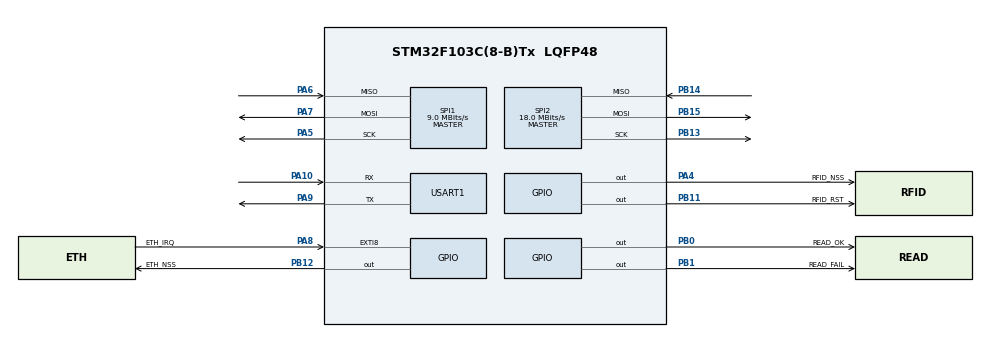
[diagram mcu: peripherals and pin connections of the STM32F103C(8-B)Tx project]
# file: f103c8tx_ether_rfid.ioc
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Mcu.Family=STM32F1
Mcu.Name=STM32F103C(8-B)Tx
Mcu.Package=LQFP48
NVIC.PriorityGroup=NVIC_PRIORITYGROUP_4
PA10.Mode=Asynchronous
PA10.Signal=USART1_RX
PA13.Mode=Trace_Asynchronous_SW
PA13.Signal=SYS_JTMS-SWDIO
PA14.Mode=Trace_Asynchronous_SW
PA14.Signal=SYS_JTCK-SWCLK
PA4.GPIO_Label=RFID_NSS
PA4.GPIO_Speed=GPIO_SPEED_FREQ_HIGH
PA4.PinState=GPIO_PIN_SET
PA4.Signal=GPIO_Output
PA5.Mode=Full_Duplex_Master
PA5.Signal=SPI1_SCK
PA6.Mode=Full_Duplex_Master
PA6.Signal=SPI1_MISO
PA7.Mode=Full_Duplex_Master
PA7.Signal=SPI1_MOSI
PA8.GPIO_Label=ETH_IRQ
PA8.GPIO_ModeDefaultEXTI=GPIO_MODE_IT_FALLING
PA8.GPIO_PuPd=GPIO_PULLUP
PA8.Signal=GPXTI8
PA9.Mode=Asynchronous
PA9.Signal=USART1_TX
PB0.GPIO_Label=READ_OK
PB0.GPIO_Speed=GPIO_SPEED_FREQ_HIGH
PB0.Signal=GPIO_Output
PB1.GPIO_Label=READ_FAIL
PB1.GPIO_Speed=GPIO_SPEED_FREQ_HIGH
PB1.Signal=GPIO_Output
PB11.GPIO_Label=RFID_RST
PB11.GPIO_Speed=GPIO_SPEED_FREQ_HIGH
PB11.Signal=GPIO_Output
PB12.GPIO_Label=ETH_NSS
PB12.GPIO_Speed=GPIO_SPEED_FREQ_HIGH
PB12.PinState=GPIO_PIN_SET
PB12.Signal=GPIO_Output
PB13.Mode=Full_Duplex_Master
PB13.Signal=SPI2_SCK
PB14.Mode=Full_Duplex_Master
PB14.Signal=SPI2_MISO
PB15.Mode=Full_Duplex_Master
PB15.Signal=SPI2_MOSI
PB3.Mode=Trace_Asynchronous_SW
PB3.Signal=SYS_JTDO-TRACESWO
PD0-OSC_IN.Mode=HSE-External-Oscillator
PD0-OSC_IN.Signal=RCC_OSC_IN
PD1-OSC_OUT.Mode=HSE-External-Oscillator
PD1-OSC_OUT.Signal=RCC_OSC_OUT
ProjectManager.HeapSize=0x200
ProjectManager.StackSize=0x400
ProjectManager.TargetToolchain=CMake
RCC.AHBFreq_Value=72000000
RCC.APB1CLKDivider=RCC_HCLK_DIV2
RCC.APB1Freq_Value=36000000
RCC.APB1TimFreq_Value=72000000
RCC.APB2Freq_Value=72000000
RCC.APB2TimFreq_Value=72000000
RCC.HCLKFreq_Value=72000000
RCC.PLLMUL=RCC_PLL_MUL9
RCC.PLLSourceVirtual=RCC_PLLSOURCE_HSE
RCC.SYSCLKFreq_VALUE=72000000
RCC.SYSCLKSource=RCC_SYSCLKSOURCE_PLLCLK
RCC.USBFreq_Value=72000000
SPI1.BaudRatePrescaler=SPI_BAUDRATEPRESCALER_8
SPI1.CalculateBaudRate=9.0 MBits/s
SPI1.Direction=SPI_DIRECTION_2LINES
SPI1.Mode=SPI_MODE_MASTER
SPI1.VirtualType=VM_MASTER
SPI2.CalculateBaudRate=18.0 MBits/s
SPI2.Direction=SPI_DIRECTION_2LINES
SPI2.Mode=SPI_MODE_MASTER
SPI2.VirtualType=VM_MASTER
USART1.VirtualMode=VM_ASYNC
board=custom

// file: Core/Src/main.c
/* USER CODE BEGIN Header */
/**
  ******************************************************************************
  * @file           : main.c
  * @brief          : Main program body
  ******************************************************************************
  * @attention
  *
  * Copyright (c) 2024 STMicroelectronics.
  * All rights reserved.
  *
  * This software is licensed under terms that can be found in the LICENSE file
  * in the root directory of this software component.
  * If no LICENSE file comes with this software, it is provided AS-IS.
  *
  ******************************************************************************
  */
/* USER CODE END Header */
#include "main.h"

/* USER CODE BEGIN Includes */
#include "app.h"
/* USER CODE END Includes */

void SystemClock_Config(void);
static void MX_GPIO_Init(void);
static void MX_SPI1_Init(void);
static void MX_SPI2_Init(void);
static void MX_USART1_UART_Init(void);

/* USER CODE BEGIN 0 */
int _write(int file, char *ptr, int len)
{
  for(int i = 0; i < len; i++)
  {
    while (!(LL_USART_IsActiveFlag_TXE(USART1)))
      ;
    LL_USART_TransmitData8(USART1, *ptr++);
  }
  return len;
}
/* USER CODE END 0 */

int main(void)
{

  /* MCU Configuration--------------------------------------------------------*/

  /* Reset of all peripherals, Initializes the Flash interface and the Systick. */
  LL_APB2_GRP1_EnableClock(LL_APB2_GRP1_PERIPH_AFIO);
  LL_APB1_GRP1_EnableClock(LL_APB1_GRP1_PERIPH_PWR);

  /* System interrupt init*/
  NVIC_SetPriorityGrouping(NVIC_PRIORITYGROUP_4);

  /* SysTick_IRQn interrupt configuration */
  NVIC_SetPriority(SysTick_IRQn, NVIC_EncodePriority(NVIC_GetPriorityGrouping(),15, 0));

  /** NOJTAG: JTAG-DP Disabled and SW-DP Enabled
  */
  LL_GPIO_AF_Remap_SWJ_NOJTAG();

  /* Configure the system clock */
  SystemClock_Config();

  /* Initialize all configured peripherals */
  MX_GPIO_Init();
  MX_SPI1_Init();
  MX_SPI2_Init();
  MX_USART1_UART_Init();
  /* USER CODE BEGIN 2 */
  app_main();
  /* USER CODE END 2 */

  /* Infinite loop */
  while (1)
  {

  }
}

void SystemClock_Config(void)
{
  LL_FLASH_SetLatency(LL_FLASH_LATENCY_2);
  while(LL_FLASH_GetLatency()!= LL_FLASH_LATENCY_2)
  {
  }
  LL_RCC_HSE_Enable();

   /* Wait till HSE is ready */
  while(LL_RCC_HSE_IsReady() != 1)
  {

  }
  LL_RCC_PLL_ConfigDomain_SYS(LL_RCC_PLLSOURCE_HSE_DIV_1, LL_RCC_PLL_MUL_9);
  LL_RCC_PLL_Enable();

   /* Wait till PLL is ready */
  while(LL_RCC_PLL_IsReady() != 1)
  {

  }
  LL_RCC_SetAHBPrescaler(LL_RCC_SYSCLK_DIV_1);
  LL_RCC_SetAPB1Prescaler(LL_RCC_APB1_DIV_2);
  LL_RCC_SetAPB2Prescaler(LL_RCC_APB2_DIV_1);
  LL_RCC_SetSysClkSource(LL_RCC_SYS_CLKSOURCE_PLL);

   /* Wait till System clock is ready */
  while(LL_RCC_GetSysClkSource() != LL_RCC_SYS_CLKSOURCE_STATUS_PLL)
  {

  }
  LL_Init1msTick(72000000);
  LL_SetSystemCoreClock(72000000);
}

static void MX_SPI1_Init(void)
{

  LL_SPI_InitTypeDef SPI_InitStruct = {0};

  LL_GPIO_InitTypeDef GPIO_InitStruct = {0};

  /* Peripheral clock enable */
  LL_APB2_GRP1_EnableClock(LL_APB2_GRP1_PERIPH_SPI1);

  LL_APB2_GRP1_EnableClock(LL_APB2_GRP1_PERIPH_GPIOA);
  /**SPI1 GPIO Configuration
  PA5   ------> SPI1_SCK
  PA6   ------> SPI1_MISO
  PA7   ------> SPI1_MOSI
  */
  GPIO_InitStruct.Pin = LL_GPIO_PIN_5|LL_GPIO_PIN_7;
  GPIO_InitStruct.Mode = LL_GPIO_MODE_ALTERNATE;
  GPIO_InitStruct.Speed = LL_GPIO_SPEED_FREQ_HIGH;
  GPIO_InitStruct.OutputType = LL_GPIO_OUTPUT_PUSHPULL;
  LL_GPIO_Init(GPIOA, &GPIO_InitStruct);

  GPIO_InitStruct.Pin = LL_GPIO_PIN_6;
  GPIO_InitStruct.Mode = LL_GPIO_MODE_FLOATING;
  LL_GPIO_Init(GPIOA, &GPIO_InitStruct);

  /* SPI1 parameter configuration*/
  SPI_InitStruct.TransferDirection = LL_SPI_FULL_DUPLEX;
  SPI_InitStruct.Mode = LL_SPI_MODE_MASTER;
  SPI_InitStruct.DataWidth = LL_SPI_DATAWIDTH_8BIT;
  SPI_InitStruct.ClockPolarity = LL_SPI_POLARITY_LOW;
  SPI_InitStruct.ClockPhase = LL_SPI_PHASE_1EDGE;
  SPI_InitStruct.NSS = LL_SPI_NSS_SOFT;
  SPI_InitStruct.BaudRate = LL_SPI_BAUDRATEPRESCALER_DIV8;
  SPI_InitStruct.BitOrder = LL_SPI_MSB_FIRST;
  SPI_InitStruct.CRCCalculation = LL_SPI_CRCCALCULATION_DISABLE;
  SPI_InitStruct.CRCPoly = 10;
  LL_SPI_Init(SPI1, &SPI_InitStruct);

}

static void MX_SPI2_Init(void)
{

  LL_SPI_InitTypeDef SPI_InitStruct = {0};

  LL_GPIO_InitTypeDef GPIO_InitStruct = {0};

  /* Peripheral clock enable */
  LL_APB1_GRP1_EnableClock(LL_APB1_GRP1_PERIPH_SPI2);

  LL_APB2_GRP1_EnableClock(LL_APB2_GRP1_PERIPH_GPIOB);
  /**SPI2 GPIO Configuration
  PB13   ------> SPI2_SCK
  PB14   ------> SPI2_MISO
  PB15   ------> SPI2_MOSI
  */
  GPIO_InitStruct.Pin = LL_GPIO_PIN_13|LL_GPIO_PIN_15;
  GPIO_InitStruct.Mode = LL_GPIO_MODE_ALTERNATE;
  GPIO_InitStruct.Speed = LL_GPIO_SPEED_FREQ_HIGH;
  GPIO_InitStruct.OutputType = LL_GPIO_OUTPUT_PUSHPULL;
  LL_GPIO_Init(GPIOB, &GPIO_InitStruct);

  GPIO_InitStruct.Pin = LL_GPIO_PIN_14;
  GPIO_InitStruct.Mode = LL_GPIO_MODE_FLOATING;
  LL_GPIO_Init(GPIOB, &GPIO_InitStruct);

  /* SPI2 parameter configuration*/
  SPI_InitStruct.TransferDirection = LL_SPI_FULL_DUPLEX;
  SPI_InitStruct.Mode = LL_SPI_MODE_MASTER;
  SPI_InitStruct.DataWidth = LL_SPI_DATAWIDTH_8BIT;
  SPI_InitStruct.ClockPolarity = LL_SPI_POLARITY_LOW;
  SPI_InitStruct.ClockPhase = LL_SPI_PHASE_1EDGE;
  SPI_InitStruct.NSS = LL_SPI_NSS_SOFT;
  SPI_InitStruct.BaudRate = LL_SPI_BAUDRATEPRESCALER_DIV2;
  SPI_InitStruct.BitOrder = LL_SPI_MSB_FIRST;
  SPI_InitStruct.CRCCalculation = LL_SPI_CRCCALCULATION_DISABLE;
  SPI_InitStruct.CRCPoly = 10;
  LL_SPI_Init(SPI2, &SPI_InitStruct);

}

static void MX_USART1_UART_Init(void)
{

  LL_USART_InitTypeDef USART_InitStruct = {0};

  LL_GPIO_InitTypeDef GPIO_InitStruct = {0};

  /* Peripheral clock enable */
  LL_APB2_GRP1_EnableClock(LL_APB2_GRP1_PERIPH_USART1);

  LL_APB2_GRP1_EnableClock(LL_APB2_GRP1_PERIPH_GPIOA);
  /**USART1 GPIO Configuration
  PA9   ------> USART1_TX
  PA10   ------> USART1_RX
  */
  GPIO_InitStruct.Pin = LL_GPIO_PIN_9;
  GPIO_InitStruct.Mode = LL_GPIO_MODE_ALTERNATE;
  GPIO_InitStruct.Speed = LL_GPIO_SPEED_FREQ_HIGH;
  GPIO_InitStruct.OutputType = LL_GPIO_OUTPUT_PUSHPULL;
  LL_GPIO_Init(GPIOA, &GPIO_InitStruct);

  GPIO_InitStruct.Pin = LL_GPIO_PIN_10;
  GPIO_InitStruct.Mode = LL_GPIO_MODE_FLOATING;
  LL_GPIO_Init(GPIOA, &GPIO_InitStruct);

  USART_InitStruct.BaudRate = 115200;
  USART_InitStruct.DataWidth = LL_USART_DATAWIDTH_8B;
  USART_InitStruct.StopBits = LL_USART_STOPBITS_1;
  USART_InitStruct.Parity = LL_USART_PARITY_NONE;
  USART_InitStruct.TransferDirection = LL_USART_DIRECTION_TX_RX;
  USART_InitStruct.HardwareFlowControl = LL_USART_HWCONTROL_NONE;
  USART_InitStruct.OverSampling = LL_USART_OVERSAMPLING_16;
  LL_USART_Init(USART1, &USART_InitStruct);
  LL_USART_ConfigAsyncMode(USART1);
  LL_USART_Enable(USART1);

}

static void MX_GPIO_Init(void)
{
  LL_EXTI_InitTypeDef EXTI_InitStruct = {0};
  LL_GPIO_InitTypeDef GPIO_InitStruct = {0};

  /* GPIO Ports Clock Enable */
  LL_APB2_GRP1_EnableClock(LL_APB2_GRP1_PERIPH_GPIOD);
  LL_APB2_GRP1_EnableClock(LL_APB2_GRP1_PERIPH_GPIOA);
  LL_APB2_GRP1_EnableClock(LL_APB2_GRP1_PERIPH_GPIOB);

  /**/
  LL_GPIO_SetOutputPin(RFID_NSS_GPIO_Port, RFID_NSS_Pin);

  /**/
  LL_GPIO_SetOutputPin(ETH_NSS_GPIO_Port, ETH_NSS_Pin);

  /**/
  LL_GPIO_ResetOutputPin(GPIOB, READ_OK_Pin|READ_FAIL_Pin|RFID_RST_Pin);

  /**/
  GPIO_InitStruct.Pin = RFID_NSS_Pin;
  GPIO_InitStruct.Mode = LL_GPIO_MODE_OUTPUT;
  GPIO_InitStruct.Speed = LL_GPIO_SPEED_FREQ_HIGH;
  GPIO_InitStruct.OutputType = LL_GPIO_OUTPUT_PUSHPULL;
  LL_GPIO_Init(RFID_NSS_GPIO_Port, &GPIO_InitStruct);

  /**/
  GPIO_InitStruct.Pin = READ_OK_Pin|READ_FAIL_Pin|RFID_RST_Pin|ETH_NSS_Pin;
  GPIO_InitStruct.Mode = LL_GPIO_MODE_OUTPUT;
  GPIO_InitStruct.Speed = LL_GPIO_SPEED_FREQ_HIGH;
  GPIO_InitStruct.OutputType = LL_GPIO_OUTPUT_PUSHPULL;
  LL_GPIO_Init(GPIOB, &GPIO_InitStruct);

  /**/
  LL_GPIO_AF_SetEXTISource(LL_GPIO_AF_EXTI_PORTA, LL_GPIO_AF_EXTI_LINE8);

  /**/
  EXTI_InitStruct.Line_0_31 = LL_EXTI_LINE_8;
  EXTI_InitStruct.LineCommand = ENABLE;
  EXTI_InitStruct.Mode = LL_EXTI_MODE_IT;
  EXTI_InitStruct.Trigger = LL_EXTI_TRIGGER_FALLING;
  LL_EXTI_Init(&EXTI_InitStruct);

  /**/
  LL_GPIO_SetPinPull(ETH_IRQ_GPIO_Port, ETH_IRQ_Pin, LL_GPIO_PULL_UP);

  /**/
  LL_GPIO_SetPinMode(ETH_IRQ_GPIO_Port, ETH_IRQ_Pin, LL_GPIO_MODE_INPUT);

}

void Error_Handler(void)
{
  __disable_irq();
  while (1)
  {
  }
}
